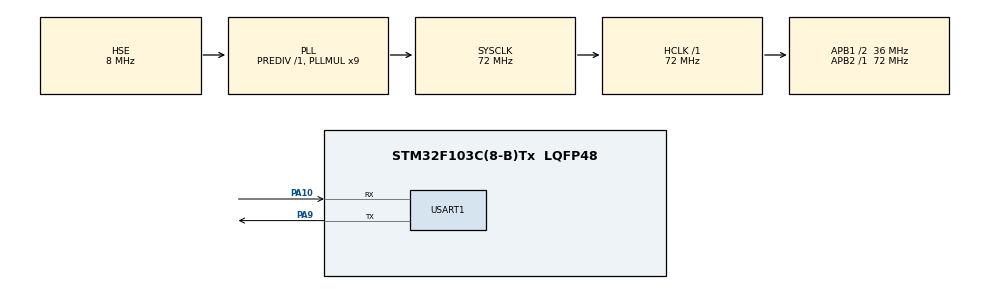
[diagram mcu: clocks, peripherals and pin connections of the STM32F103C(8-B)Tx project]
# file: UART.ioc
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Mcu.Family=STM32F1
Mcu.Name=STM32F103C(8-B)Tx
Mcu.Package=LQFP48
NVIC.PriorityGroup=NVIC_PRIORITYGROUP_4
PA10.Mode=Asynchronous
PA10.Signal=USART1_RX
PA9.Mode=Asynchronous
PA9.Signal=USART1_TX
PD0-OSC_IN.Mode=HSE-External-Oscillator
PD0-OSC_IN.Signal=RCC_OSC_IN
PD1-OSC_OUT.Mode=HSE-External-Oscillator
PD1-OSC_OUT.Signal=RCC_OSC_OUT
ProjectManager.HeapSize=0x200
ProjectManager.StackSize=0x400
ProjectManager.TargetToolchain=STM32CubeIDE
RCC.AHBFreq_Value=72000000
RCC.APB1CLKDivider=RCC_HCLK_DIV2
RCC.APB1Freq_Value=36000000
RCC.APB1TimFreq_Value=72000000
RCC.APB2Freq_Value=72000000
RCC.APB2TimFreq_Value=72000000
RCC.HCLKFreq_Value=72000000
RCC.PLLMUL=RCC_PLL_MUL9
RCC.PLLSourceVirtual=RCC_PLLSOURCE_HSE
RCC.SYSCLKFreq_VALUE=72000000
RCC.SYSCLKSource=RCC_SYSCLKSOURCE_PLLCLK
RCC.USBFreq_Value=72000000
USART1.VirtualMode=VM_ASYNC
board=custom

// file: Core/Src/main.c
/* USER CODE END Header */
#include "main.h"
#include "usart.h"
#include "gpio.h"
#include <stdio.h>
#include <string.h>

char tx[40];
char rx[40];

HAL_StatusTypeDef receive;

void SystemClock_Config(void);

int main(void)
{

  /* Reset of all peripherals, Initializes the Flash interface and the Systick. */
  HAL_Init();

  /* Configure the system clock */
  SystemClock_Config();

  /* Initialize all configured peripherals */
  MX_GPIO_Init();
  MX_USART1_UART_Init();

  /* Infinite loop */
  /* USER CODE BEGIN WHILE */
  while (1)
  {

	  // Envía un mensaje desde el microcontrolador STM32 a través de la UART
	  sprintf(tx, "Mensaje desde stm32 \n\r"); // Formatea el mensaje y lo guarda en el búfer tx
	  HAL_UART_Transmit(&huart1, (uint8_t*)tx, strlen(tx), HAL_MAX_DELAY); // Transmite el mensaje a través de la UART

	  // Espera 300 milisegundos para asegurar que la transmisión anterior haya completado
	  HAL_Delay(300);

	  // Recibe un dato a través de la UART
	  receive = HAL_UART_Receive(&huart1, (uint8_t*)tx, strlen(tx), HAL_MAX_DELAY);

	  // Verifica si la recepción fue exitosa
	  if(receive == HAL_OK)
	  {
	      // Extrae el primer caracter recibido
	      char caracter = rx[0];

	      // Construye un mensaje con el dato recibido y lo envía a través de la UART
	      sprintf(tx, "Dato recibido: %c\r\n", caracter); // Formatea el mensaje con el dato recibido
	      HAL_UART_Transmit(&huart1, (uint8_t*)tx, strlen(tx), HAL_MAX_DELAY); // Transmite el mensaje a través de la UART
	  }

    /* USER CODE END WHILE */

  }
}

void SystemClock_Config(void)
{
  RCC_OscInitTypeDef RCC_OscInitStruct = {0};
  RCC_ClkInitTypeDef RCC_ClkInitStruct = {0};

  /** Initializes the RCC Oscillators according to the specified parameters
  * in the RCC_OscInitTypeDef structure.
  */
  RCC_OscInitStruct.OscillatorType = RCC_OSCILLATORTYPE_HSE;
  RCC_OscInitStruct.HSEState = RCC_HSE_ON;
  RCC_OscInitStruct.HSEPredivValue = RCC_HSE_PREDIV_DIV1;
  RCC_OscInitStruct.HSIState = RCC_HSI_ON;
  RCC_OscInitStruct.PLL.PLLState = RCC_PLL_ON;
  RCC_OscInitStruct.PLL.PLLSource = RCC_PLLSOURCE_HSE;
  RCC_OscInitStruct.PLL.PLLMUL = RCC_PLL_MUL9;
  if (HAL_RCC_OscConfig(&RCC_OscInitStruct) != HAL_OK)
  {
    Error_Handler();
  }

  /** Initializes the CPU, AHB and APB buses clocks
  */
  RCC_ClkInitStruct.ClockType = RCC_CLOCKTYPE_HCLK|RCC_CLOCKTYPE_SYSCLK
                              |RCC_CLOCKTYPE_PCLK1|RCC_CLOCKTYPE_PCLK2;
  RCC_ClkInitStruct.SYSCLKSource = RCC_SYSCLKSOURCE_PLLCLK;
  RCC_ClkInitStruct.AHBCLKDivider = RCC_SYSCLK_DIV1;
  RCC_ClkInitStruct.APB1CLKDivider = RCC_HCLK_DIV2;
  RCC_ClkInitStruct.APB2CLKDivider = RCC_HCLK_DIV1;

  if (HAL_RCC_ClockConfig(&RCC_ClkInitStruct, FLASH_LATENCY_2) != HAL_OK)
  {
    Error_Handler();
  }
}

void Error_Handler(void)
{
  __disable_irq();
  while (1)
  {
  }
}
